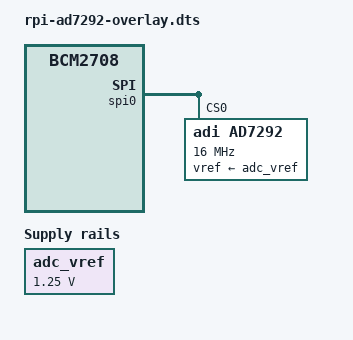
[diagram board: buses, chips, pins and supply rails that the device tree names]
/dts-v1/;
/plugin/;

/ {
	compatible = "brcm,bcm2708";

	fragment@0 {
		target-path = "/";
		__overlay__ {
			adc_vref: fixedregulator@0 {
				compatible = "regulator-fixed";
				regulator-name = "fixed-supply";
				regulator-min-microvolt = <1250000>;
				regulator-max-microvolt = <1250000>;
				regulator-boot-on;
			};
		};
	};

	fragment@1 {
		target = <&spi0>;
		__overlay__ {
			#address-cells = <1>;
			#size-cells = <0>;
			status = "okay";

			ad7292@0{
				compatible = "adi,ad7292";
				reg = <0>;
				spi-max-frequency = <16000000>;
				vref-supply = <&adc_vref>;
				spi-cpha;
				diff-channels;

				#address-cells = <1>;
				#size-cells = <0>;
			};
		};
	};
};
